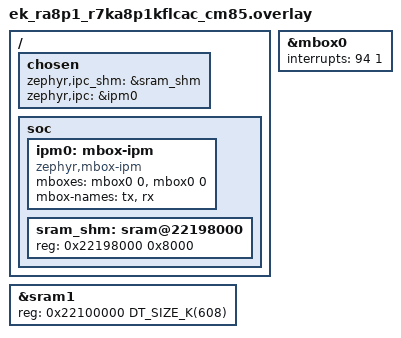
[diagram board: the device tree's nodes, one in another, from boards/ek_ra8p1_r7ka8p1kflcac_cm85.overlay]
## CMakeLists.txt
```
cmake_minimum_required(VERSION 3.28.0)
# Copyright (c) 2018 Nordic Semiconductor ASA
# Copyright (c) 2019 Linaro Limited
# Copyright 2022 NXP
#
# SPDX-License-Identifier: Apache-2.0
#

set(REMOTE_ZEPHYR_DIR ${CMAKE_CURRENT_BINARY_DIR}/../openamp_remote/zephyr)


find_package(Zephyr REQUIRED HINTS $ENV{ZEPHYR_BASE})
project(openamp)

message(STATUS "${BOARD} compile as Master in this sample")

if(CONFIG_INCLUDE_REMOTE_DIR)
  target_include_directories(zephyr_interface
    INTERFACE ${REMOTE_ZEPHYR_DIR}/include/public)
endif()

enable_language(C ASM)

target_sources(app PRIVATE src/main.c)

target_include_directories(app PRIVATE ${CMAKE_CURRENT_SOURCE_DIR})
```

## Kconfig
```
# Copyright 2022 NXP
#
# SPDX-License-Identifier: Apache-2.0

source "Kconfig.zephyr"

config INCLUDE_REMOTE_DIR
	bool "Include remote core header directory"
	help
	  Include remote build header files. Can be used if primary image
	  needs to be aware of size or base address of secondary image
```

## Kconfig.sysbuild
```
# Copyright 2022-2026 NXP
#
# SPDX-License-Identifier: Apache-2.0

source "share/sysbuild/Kconfig"

config OPENAMP_REMOTE_BOARD
string
	default "lpcxpresso54114/lpc54114/m0" if $(BOARD) = "lpcxpresso54114"
	default "lpcxpresso55s69/lpc55s69/cpu1" if $(BOARD) = "lpcxpresso55s69"
	default "mps2/an521/cpu1" if $(BOARD) = "mps2"
	default "mps3/an524/cpu1" if $(BOARD) = "mps3"
	default "v2m_musca_b1/musca_b1/ns" if $(BOARD) = "v2m_musca_b1"
	default "mimxrt1170_evk/mimxrt1176/cm4" if $(BOARD) = "mimxrt1170_evk"
	default "mimxrt1160_evk/mimxrt1166/cm4" if $(BOARD) = "mimxrt1160_evk"
	default "mimxrt1170_evkb/mimxrt1176/cm4" if $(BOARD) = "mimxrt1170_evkb"
	default "frdm_mcxn947/mcxn947/cpu1" if $(BOARD) = "frdm_mcxn947"
	default "mcx_n9xx_evk/mcxn947/cpu1" if $(BOARD) = "mcx_n9xx_evk"
	default "mimxrt1180_evk/mimxrt1189/cm7" if $(BOARD) = "mimxrt1180_evk"
	default "frdm_imxrt1186/mimxrt1186/cm7" if $(BOARD) = "frdm_imxrt1186"
	default "mimxrt700_evk/mimxrt798s/cm33_cpu1" if $(BOARD) = "mimxrt700_evk"
	default "esp32s3_devkitc/esp32s3/appcpu" if $(BOARD) = "esp32s3_devkitc"
	default "esp32_devkitc/esp32/appcpu" if $(BOARD) = "esp32_devkitc"
	default "esp_wrover_kit/esp32/appcpu" if $(BOARD) = "esp_wrover_kit"
	default "esp32_ethernet_kit/esp32/appcpu" if $(BOARD) = "esp32_ethernet_kit"
	default "ek_ra8m2/r7ka8m2jflcac/cm33" if $(BOARD) = "ek_ra8m2"
	default "ek_ra8p1/r7ka8p1kflcac/cm33" if $(BOARD) = "ek_ra8p1"
	default "ek_ra8d2/r7ka8d2kflcac/cm33" if $(BOARD) = "ek_ra8d2"
	default "ek_ra8t2/r7ka8t2lflcac/cm33" if $(BOARD) = "ek_ra8t2"
	default "mck_ra8t2/r7ka8t2lflcac/cm33" if $(BOARD) = "mck_ra8t2"
	default "imx943_evk/mimx94398/m33" if "$(BOARD)/$(BOARD_QUALIFIERS)" = "imx943_evk/mimx94398/m7_1"
	default "imx943_evk/mimx94398/m33" if "$(BOARD)/$(BOARD_QUALIFIERS)" = "imx943_evk/mimx94398/m7_0"
	default "imx943_evk/mimx94398/m7_1" if "$(BOARD)/$(BOARD_QUALIFIERS)" = "imx943_evk/mimx94398/m33"
```

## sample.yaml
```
sample:
  description: This app provides an example of how to integrate OpenAMP with Zephyr.
  name: OpenAMP example integration
tests:
  sample.ipc.openamp:
    filter: dt_chosen_enabled("zephyr,ipc") and dt_chosen_enabled("zephyr,ipc_shm")
      and not (CONFIG_SOC_ESP32_APPCPU or CONFIG_SOC_ESP32S3_APPCPU)
    integration_platforms:
      - mps2/an521/cpu0
    tags:
      - ipm
      - openamp
    harness: console
    sysbuild: true
    harness_config:
      type: multi_line
      regex:
        - "Master core received a message: 1"
        - "Master core received a message: 99"
        - "OpenAMP demo ended."
```

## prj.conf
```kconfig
CONFIG_PRINTK=y
CONFIG_IPM=y
CONFIG_TIMESLICE_SIZE=1
CONFIG_MAIN_STACK_SIZE=2048
CONFIG_HEAP_MEM_POOL_SIZE=4096
CONFIG_OPENAMP=y
CONFIG_OPENAMP_SLAVE=n
CONFIG_BOARD_SUPPORT_REMOTE_ENDPOINT=y
```

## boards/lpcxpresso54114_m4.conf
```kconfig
CONFIG_SECOND_CORE_MCUX=y
CONFIG_SECOND_IMAGE_MCUX="${ZEPHYR_BINARY_DIR}/../openamp_remote-prefix/src/openamp_remote-build/zephyr/${KERNEL_BIN_NAME}"
```

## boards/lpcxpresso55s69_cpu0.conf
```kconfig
CONFIG_SECOND_CORE_MCUX=y
CONFIG_SECOND_IMAGE_MCUX="${ZEPHYR_BINARY_DIR}/../openamp_remote-prefix/src/openamp_remote-build/zephyr/zephyr.bin"
```

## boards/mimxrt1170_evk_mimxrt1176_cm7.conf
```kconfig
#
# Copyright 2023, NXP
#
# SPDX-License-Identifier: Apache-2.0
#
CONFIG_INCLUDE_REMOTE_DIR=y
CONFIG_SECOND_CORE_MCUX=y
```

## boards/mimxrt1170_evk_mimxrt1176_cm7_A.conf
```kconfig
CONFIG_INCLUDE_REMOTE_DIR=y
CONFIG_SECOND_CORE_MCUX=y
```

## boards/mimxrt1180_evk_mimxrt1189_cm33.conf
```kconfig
CONFIG_SECOND_CORE_MCUX=y
CONFIG_INCLUDE_REMOTE_DIR=y
CONFIG_MBOX=y
```

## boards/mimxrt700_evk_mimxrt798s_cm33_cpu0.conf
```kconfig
#
# Copyright 2025 NXP
#
# SPDX-License-Identifier: Apache-2.0
#

CONFIG_INCLUDE_REMOTE_DIR=y
CONFIG_SECOND_CORE_MCUX=y
```

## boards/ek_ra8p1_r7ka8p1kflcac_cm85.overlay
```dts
/*
 * Copyright (c) 2025 Renesas Electronics Corporation
 * SPDX-License-Identifier: Apache-2.0
 */

/ {
	chosen {
		/*
		 * shared memory reserved for the inter-processor communication
		 */

		zephyr,ipc_shm = &sram_shm;
		zephyr,ipc = &ipm0;
	};

	soc {
		ipm0: mbox-ipm {
			compatible = "zephyr,mbox-ipm";
			mboxes = <&mbox0 0>, <&mbox0 0>;
			mbox-names = "tx", "rx";
			status = "okay";
		};

		/* Define shared memory regions for IPC */
		sram_shm: sram@22198000 {
			reg = <0x22198000 0x8000>;
		};
	};
};

/* Redefine sram size for CPU1 */
&sram1 {
	reg = <0x22100000 DT_SIZE_K(608)>;
};

&mbox0 {
	interrupts = <94 1>;
	status = "okay";
};
```

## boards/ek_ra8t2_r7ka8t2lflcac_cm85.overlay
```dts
/*
 * Copyright (c) 2026 Renesas Electronics Corporation
 * SPDX-License-Identifier: Apache-2.0
 */

/ {
	chosen {
		/*
		 * shared memory reserved for the inter-processor communication
		 */

		zephyr,ipc_shm = &sram_shm;
		zephyr,ipc = &ipm0;
	};

	soc {
		ipm0: mbox-ipm {
			compatible = "zephyr,mbox-ipm";
			mboxes = <&mbox0 0>, <&mbox0 0>;
			mbox-names = "tx", "rx";
			status = "okay";
		};

		/* Define shared memory regions for IPC */
		sram_shm: sram@22198000 {
			reg = <0x22198000 0x8000>;
		};
	};
};

/* Redefine sram size for CPU1 */
&sram1 {
	reg = <0x22100000 DT_SIZE_K(608)>;
};

&mbox0 {
	interrupts = <94 1>;
	status = "okay";
};
```

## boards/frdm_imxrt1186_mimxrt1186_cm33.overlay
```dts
/*
 * Copyright 2026 NXP
 *
 * SPDX-License-Identifier: Apache-2.0
 */

#include <zephyr/dt-bindings/ipc_service/static_vrings.h>
#include <zephyr/dt-bindings/memory-attr/memory-attr-arm.h>

/ {
	chosen {
		/*
		 * shared memory reserved for the inter-processor communication
		 */

		zephyr,ipc_shm = &ocram2_sh_mem;
		zephyr,ipc = &mailbox_a;
	};

	mailbox_a: ipm-mbox {
		compatible = "zephyr,mbox-ipm";
		mboxes = <&mbox1_a 1>, <&mbox1_a 0>;
		mbox-names = "tx", "rx";
	};

	/* Define memory regions for IPC */
	ocram2_sh_mem: memory@20500000 {
		compatible = "zephyr,memory-region", "mmio-sram";
		reg = <0x20500000 DT_SIZE_K(32)>;
		zephyr,memory-region = "OCRAM2_SH_MEM";
		zephyr,memory-attr = <DT_MEM_ARM(ATTR_MPU_RAM_NOCACHE)>;
	};
};
```

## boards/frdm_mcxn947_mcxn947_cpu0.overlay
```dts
/*
 * Copyright 2024 NXP
 *
 * SPDX-License-Identifier: Apache-2.0
 */

/ {
	chosen {
		/*
		 * shared memory reserved for the inter-processor communication
		 */

		zephyr,ipc_shm = &sramh;
		zephyr,ipc = &mailbox0;
	};

	/* Delete MBOX Driver node */
	/delete-node/ mbox@b2000;

	soc {
		mailbox0: mailbox@400b2000 {
			compatible = "nxp,lpc-mailbox";
			reg = <0x400b2000 0xec>;
			interrupts = <54 0>;
			resets = <&reset NXP_SYSCON_RESET(0, 26)>;
			status = "okay";
		};
	};
};
```

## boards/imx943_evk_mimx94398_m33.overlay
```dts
/*
 * Copyright 2025 NXP
 *
 * SPDX-License-Identifier: Apache-2.0
 */

#include <zephyr/dt-bindings/ipc_service/static_vrings.h>
#include <zephyr/dt-bindings/memory-attr/memory-attr-arm.h>

/ {
	chosen {
		/*
		 * shared memory reserved for the inter-processor communication
		 */

		zephyr,ipc_shm = &dram_m33s_m71_sh_mem;
		zephyr,ipc = &mailbox_m33s_m71_for_m33s_as_master;
	};
};
```

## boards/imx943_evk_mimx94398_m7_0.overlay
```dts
/*
 * Copyright 2025 NXP
 *
 * SPDX-License-Identifier: Apache-2.0
 */

#include <zephyr/dt-bindings/ipc_service/static_vrings.h>
#include <zephyr/dt-bindings/memory-attr/memory-attr-arm.h>

/ {
	chosen {
		/*
		 * shared memory reserved for the inter-processor communication
		 */

		zephyr,ipc_shm = &dram_m33s_m70_sh_mem;
		zephyr,ipc = &mailbox_m33s_m70_for_m70_as_master;
	};
};
```

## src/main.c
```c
/*
 * Copyright (c) 2018, NXP
 * Copyright (c) 2018, Nordic Semiconductor ASA
 * Copyright (c) 2018-2019, Linaro Limited
 *
 * SPDX-License-Identifier: Apache-2.0
 */

#include <zephyr/kernel.h>
#include <zephyr/drivers/ipm.h>
#include <zephyr/sys/printk.h>
#include <zephyr/device.h>
#include <stdio.h>
#include <stdlib.h>
#include <string.h>
#include <zephyr/init.h>

#include <openamp/open_amp.h>

#include "common.h"

#define APP_TASK_STACK_SIZE (1024)
K_THREAD_STACK_DEFINE(thread_stack, APP_TASK_STACK_SIZE);
static struct k_thread thread_data;

static const struct device *const ipm_handle =
	DEVICE_DT_GET(DT_CHOSEN(zephyr_ipc));

static metal_phys_addr_t shm_physmap[] = { SHM_START_ADDR };

static volatile unsigned int received_data;

static struct virtio_vring_info rvrings[2] = {
	[0] = {
		.info.align = VRING_ALIGNMENT,
	},
	[1] = {
		.info.align = VRING_ALIGNMENT,
	},
};
static struct virtio_device vdev;
static struct rpmsg_virtio_device rvdev;
static struct metal_io_region shm_io_data;
static struct metal_io_region *io = &shm_io_data;
static struct virtqueue *vqueue[2];

static unsigned char ipc_virtio_get_status(struct virtio_device *dev)
{
	return VIRTIO_CONFIG_STATUS_DRIVER_OK;
}

static void ipc_virtio_set_status(struct virtio_device *dev, unsigned char status)
{
	sys_write8(status, VDEV_STATUS_ADDR);
}

static uint32_t ipc_virtio_get_features(struct virtio_device *dev)
{
	return 1 << VIRTIO_RPMSG_F_NS;
}

static void ipc_virtio_set_features(struct virtio_device *dev, uint32_t features)
{
}

static void ipc_virtio_notify(struct virtqueue *vq)
{
#if defined(CONFIG_SOC_AN521) || \
	defined(CONFIG_SOC_AN524) || \
	defined(CONFIG_SOC_MUSCA_B1)
	uint32_t current_core = sse_200_platform_get_cpu_id();

	ipm_send(ipm_handle, 0, current_core ? 0 : 1, 0, 1);
#else
	uint32_t dummy_data = 0x55005500; /* Some data must be provided */

	ipm_send(ipm_handle, 0, 0, &dummy_data, sizeof(dummy_data));
#endif /* #if defined(CONFIG_SOC_AN521) */
}

struct virtio_dispatch dispatch = {
	.get_status = ipc_virtio_get_status,
	.set_status = ipc_virtio_set_status,
	.get_features = ipc_virtio_get_features,
	.set_features = ipc_virtio_set_features,
	.notify = ipc_virtio_notify,
};

static K_SEM_DEFINE(data_sem, 0, 1);
static K_SEM_DEFINE(data_rx_sem, 0, 1);

static void platform_ipm_callback(const struct device *dev, void *context,
				  uint32_t id, volatile void *data)
{
	k_sem_give(&data_sem);
}

int endpoint_cb(struct rpmsg_endpoint *ept, void *data,
		size_t len, uint32_t src, void *priv)
{
	received_data = *((unsigned int *) data);

	k_sem_give(&data_rx_sem);

	return RPMSG_SUCCESS;
}

static K_SEM_DEFINE(ept_sem, 0, 1);

struct rpmsg_endpoint my_ept;
struct rpmsg_endpoint *ep = &my_ept;

static void rpmsg_service_unbind(struct rpmsg_endpoint *ept)
{
	(void)ept;
	rpmsg_destroy_ept(ep);
}

void ns_bind_cb(struct rpmsg_device *rdev, const char *name, uint32_t dest)
{
	(void)rpmsg_create_ept(ep, rdev, name,
			RPMSG_ADDR_ANY, dest,
			endpoint_cb,
			rpmsg_service_unbind);

	k_sem_give(&ept_sem);
}

static unsigned int receive_message(void)
{
	while (k_sem_take(&data_rx_sem, K_NO_WAIT) != 0) {
		int status = k_sem_take(&data_sem, K_FOREVER);

		if (status == 0) {
			virtqueue_notification(vqueue[0]);
		}
	}
	return received_data;
}

static int send_message(unsigned int message)
{
	return rpmsg_send(ep, &message, sizeof(message));
}

static struct rpmsg_virtio_shm_pool shpool;

void app_task(void *arg1, void *arg2, void *arg3)
{
	ARG_UNUSED(arg1);
	ARG_UNUSED(arg2);
	ARG_UNUSED(arg3);

	int status = 0;
	unsigned int message = 0U;
	struct metal_init_params metal_params = METAL_INIT_DEFAULTS;

	printk("\r\nOpenAMP[master] demo started\r\n");

	status = metal_init(&metal_params);
	if (status != 0) {
		printk("metal_init: failed - error code %d\n", status);
		return;
	}

	/* declare shared memory region */
	metal_io_init(io, (void *)SHM_START_ADDR, shm_physmap, SHM_SIZE, -1, 0, NULL);

	/* setup IPM */
	if (!device_is_ready(ipm_handle)) {
		printk("IPM device is not ready\n");
		return;
	}

	ipm_register_callback(ipm_handle, platform_ipm_callback, NULL);

	status = ipm_set_enabled(ipm_handle, 1);
	if (status != 0) {
		printk("ipm_set_enabled failed\n");
		return;
	}

	/* setup vdev */
	vqueue[0] = virtqueue_allocate(VRING_SIZE);
	if (vqueue[0] == NULL) {
		printk("virtqueue_allocate failed to alloc vqueue[0]\n");
		return;
	}
	vqueue[1] = virtqueue_allocate(VRING_SIZE);
	if (vqueue[1] == NULL) {
		printk("virtqueue_allocate failed to alloc vqueue[1]\n");
		return;
	}

	vdev.role = RPMSG_HOST;
	vdev.vrings_num = VRING_COUNT;
	vdev.func = &dispatch;
	rvrings[0].io = io;
	rvrings[0].info.vaddr = (void *)VRING_TX_ADDRESS;
	rvrings[0].info.num_descs = VRING_SIZE;
	rvrings[0].info.align = VRING_ALIGNMENT;
	rvrings[0].vq = vqueue[0];

	rvrings[1].io = io;
	rvrings[1].info.vaddr = (void *)VRING_RX_ADDRESS;
	rvrings[1].info.num_descs = VRING_SIZE;
	rvrings[1].info.align = VRING_ALIGNMENT;
	rvrings[1].vq = vqueue[1];

	vdev.vrings_info = &rvrings[0];

	/* setup rvdev */
	rpmsg_virtio_init_shm_pool(&shpool, (void *)SHM_START_ADDR, SHM_SIZE);
	status = rpmsg_init_vdev(&rvdev, &vdev, ns_bind_cb, io, &shpool);
	if (status != 0) {
		printk("rpmsg_init_vdev failed %d\n", status);
		return;
	}

	/* Since we are using name service, we need to wait for a response
	 * from NS setup and then we need to process it
	 */
	k_sem_take(&data_sem, K_FOREVER);
	virtqueue_notification(vqueue[0]);

	/* Wait til nameservice ep is setup */
	k_sem_take(&ept_sem, K_FOREVER);

	while (message < 100) {
		status = send_message(message);
		if (status < 0) {
			printk("send_message(%d) failed with status %d\n",
			       message, status);
			goto _cleanup;
		}

		message = receive_message();
		printk("Master core received a message: %d\n", message);

		message++;
	}

_cleanup:
	rpmsg_deinit_vdev(&rvdev);
	metal_finish();

	printk("OpenAMP demo ended.\n");
}

int main(void)
{
	printk("Starting application thread!\n");
	k_thread_create(&thread_data, thread_stack, APP_TASK_STACK_SIZE,
			app_task,
			NULL, NULL, NULL, K_PRIO_COOP(7), 0, K_NO_WAIT);

#if defined(CONFIG_SOC_AN521) || \
	defined(CONFIG_SOC_AN524) || \
	defined(CONFIG_SOC_MUSCA_B1)
	wakeup_cpu1();
	k_msleep(500);
#endif /* #if defined(CONFIG_SOC_AN521) */
	return 0;
}

/* Make sure we clear out the status flag very early (before we bringup the
 * secondary core) so the secondary core see's the proper status
 */
int init_status_flag(void)
{
	ipc_virtio_set_status(NULL, 0);

	return 0;
}

SYS_INIT(init_status_flag, PRE_KERNEL_1, CONFIG_KERNEL_INIT_PRIORITY_DEFAULT);
```

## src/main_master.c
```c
/*
 * Copyright (c) 2018, NXP
 * Copyright (c) 2018, Nordic Semiconductor ASA
 *
 * SPDX-License-Identifier: Apache-2.0
 *
 * This implements the master side of an OpenAMP system.
 */

#include <zephyr.h>
#include <misc/printk.h>
#include <device.h>
#include <stdio.h>
#include <stdlib.h>
#include <string.h>

#include <openamp/open_amp.h>

#include "platform.h"
#include "resource_table.h"

#define APP_TASK_STACK_SIZE (512)
K_THREAD_STACK_DEFINE(thread_stack, APP_TASK_STACK_SIZE);
static struct k_thread thread_data;

static struct rpmsg_channel *rp_channel;
static struct rpmsg_endpoint *rp_endpoint;

static K_SEM_DEFINE(channel_created, 0, 1);

static K_SEM_DEFINE(message_received, 0, 1);
static volatile unsigned int received_data;

static struct rsc_table_info rsc_info;
static struct hil_proc *proc;

static void rpmsg_recv_callback(struct rpmsg_channel *channel, void *data,
				int data_length, void *private,
				unsigned long src)
{
	received_data = *((unsigned int *) data);
	k_sem_give(&message_received);
}

static void rpmsg_channel_created(struct rpmsg_channel *channel)
{
	rp_channel = channel;
	rp_endpoint = rpmsg_create_ept(rp_channel, rpmsg_recv_callback,
				       RPMSG_NULL, RPMSG_ADDR_ANY);
	k_sem_give(&channel_created);
}

static void rpmsg_channel_deleted(struct rpmsg_channel *channel)
{
	rpmsg_destroy_ept(rp_endpoint);
}

static unsigned int receive_message(void)
{
	while (k_sem_take(&message_received, K_NO_WAIT) != 0)
		hil_poll(proc, 0);
	return received_data;
}

static int send_message(unsigned int message)
{
	return rpmsg_send(rp_channel, &message, sizeof(message));
}

void app_task(void *arg1, void *arg2, void *arg3)
{
	ARG_UNUSED(arg1);
	ARG_UNUSED(arg2);
	ARG_UNUSED(arg3);

	printk("\r\nOpenAMP demo started\r\n");

	struct metal_init_params metal_params = METAL_INIT_DEFAULTS;

	metal_init(&metal_params);

	proc = platform_init(RPMSG_MASTER);
	if (proc == NULL) {
		printk("platform_init() failed\n");
		goto _cleanup;
	}

	resource_table_init((void **) &rsc_info.rsc_tab, &rsc_info.size);

	struct remote_proc *rproc_ptr = NULL;
	int status = remoteproc_resource_init(&rsc_info, proc,
					      rpmsg_channel_created,
					      rpmsg_channel_deleted,
					      rpmsg_recv_callback,
					      &rproc_ptr, RPMSG_MASTER);
	if (status != 0) {
		printk("remoteproc_resource_init() failed with status %d\n",
		       status);
		goto _cleanup;
	}

	while (k_sem_take(&channel_created, K_NO_WAIT) != 0)
		hil_poll(proc, 0);

	unsigned int message = 0U;

	status = send_message(message);
	if (status < 0) {
		printk("send_message(%d) failed with status %d\n",
		       message, status);
		goto _cleanup;
	}

	while (message <= 100) {
		message = receive_message();
		printk("Primary core received a message: %d\n", message);

		message++;
		status = send_message(message);
		if (status < 0) {
			printk("send_message(%d) failed with status %d\n",
			       message, status);
			goto _cleanup;
		}
	}

_cleanup:
	if (rproc_ptr) {
		remoteproc_resource_deinit(rproc_ptr);
	}
	metal_finish();

	printk("OpenAMP demo ended.\n");
}

void main(void)
{
	printk("Starting application thread!\n");
	k_thread_create(&thread_data, thread_stack, APP_TASK_STACK_SIZE,
			(k_thread_entry_t)app_task,
			NULL, NULL, NULL, K_PRIO_COOP(7), 0, 0);
}
```
